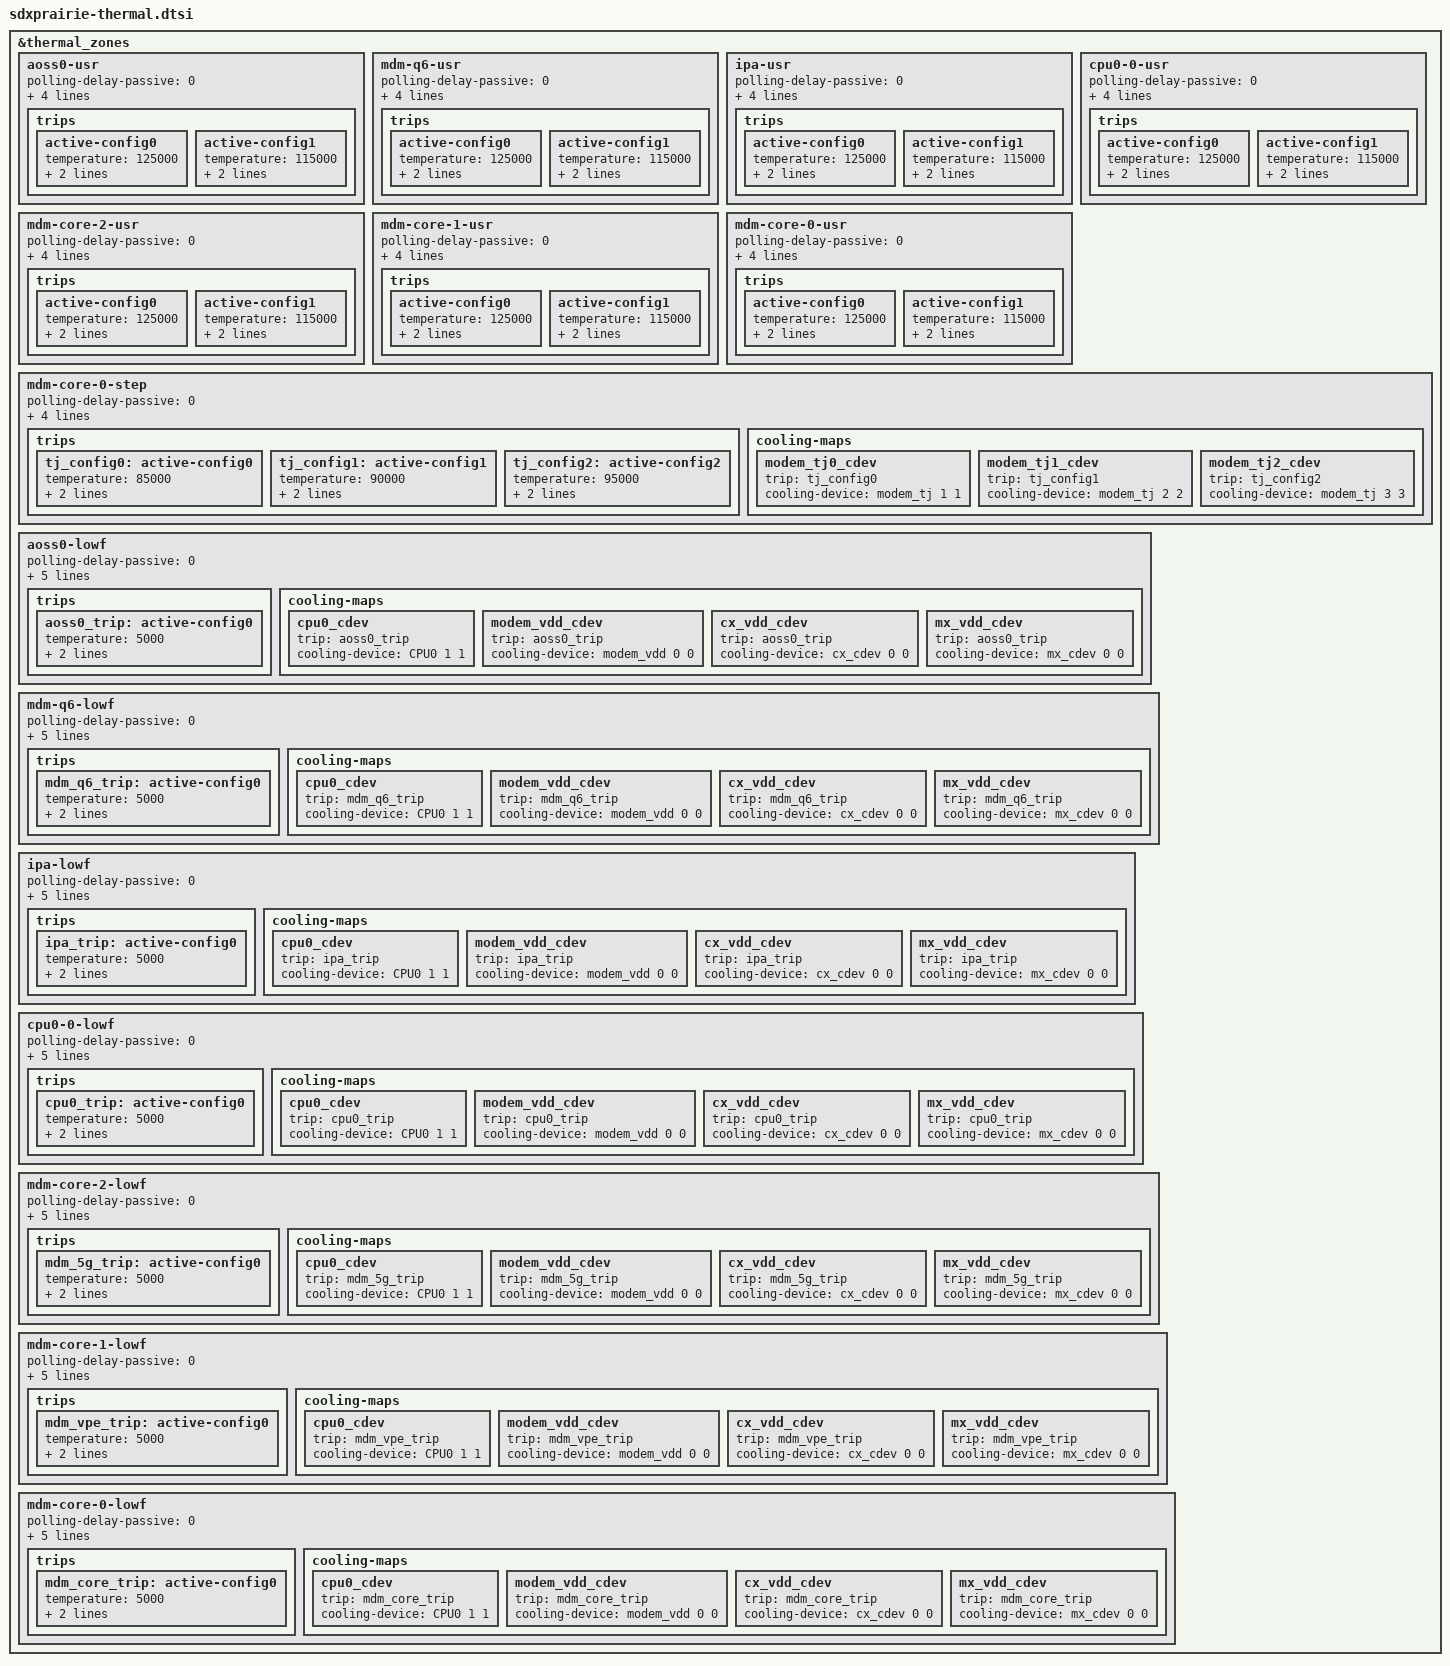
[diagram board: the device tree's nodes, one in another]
/* Copyright (c) 2019-2020, The Linux Foundation. All rights reserved.
 *
 * This program is free software; you can redistribute it and/or modify
 * it under the terms of the GNU General Public License version 2 and
 * only version 2 as published by the Free Software Foundation.
 *
 * This program is distributed in the hope that it will be useful,
 * but WITHOUT ANY WARRANTY; without even the implied warranty of
 * MERCHANTABILITY or FITNESS FOR A PARTICULAR PURPOSE.  See the
 * GNU General Public License for more details.
 */

#include <dt-bindings/thermal/thermal.h>
#include "sdxprairie-thermal-common.dtsi"

&thermal_zones {
	aoss0-usr {
		polling-delay-passive = <0>;
		polling-delay = <0>;
		thermal-governor = "user_space";
		thermal-sensors = <&tsens0 0>;
		wake-capable-sensor;
		trips {
			active-config0 {
				temperature = <125000>;
				hysteresis = <1000>;
				type = "passive";
			};
			active-config1 {
				temperature = <115000>;
				hysteresis = <5000>;
				type = "passive";
			};
		};
	};

	mdm-q6-usr {
		polling-delay-passive = <0>;
		polling-delay = <0>;
		thermal-governor = "user_space";
		thermal-sensors = <&tsens0 1>;
		wake-capable-sensor;
		trips {
			active-config0 {
				temperature = <125000>;
				hysteresis = <1000>;
				type = "passive";
			};
			active-config1 {
				temperature = <115000>;
				hysteresis = <5000>;
				type = "passive";
			};
		};
	};

	ipa-usr {
		polling-delay-passive = <0>;
		polling-delay = <0>;
		thermal-governor = "user_space";
		thermal-sensors = <&tsens0 2>;
		wake-capable-sensor;
		trips {
			active-config0 {
				temperature = <125000>;
				hysteresis = <1000>;
				type = "passive";
			};
			active-config1 {
				temperature = <115000>;
				hysteresis = <5000>;
				type = "passive";
			};
		};
	};

	cpu0-0-usr {
		polling-delay-passive = <0>;
		polling-delay = <0>;
		thermal-governor = "user_space";
		thermal-sensors = <&tsens0 3>;
		wake-capable-sensor;
		trips {
			active-config0 {
				temperature = <125000>;
				hysteresis = <1000>;
				type = "passive";
			};
			active-config1 {
				temperature = <115000>;
				hysteresis = <5000>;
				type = "passive";
			};
		};
	};

	mdm-core-2-usr {
		polling-delay-passive = <0>;
		polling-delay = <0>;
		thermal-sensors = <&tsens0 4>;
		thermal-governor = "user_space";
		wake-capable-sensor;
		trips {
			active-config0 {
				temperature = <125000>;
				hysteresis = <1000>;
				type = "passive";
			};
			active-config1 {
				temperature = <115000>;
				hysteresis = <5000>;
				type = "passive";
			};
		};
	};

	mdm-core-1-usr {
		polling-delay-passive = <0>;
		polling-delay = <0>;
		thermal-sensors = <&tsens0 5>;
		thermal-governor = "user_space";
		wake-capable-sensor;
		trips {
			active-config0 {
				temperature = <125000>;
				hysteresis = <1000>;
				type = "passive";
			};
			active-config1 {
				temperature = <115000>;
				hysteresis = <5000>;
				type = "passive";
			};
		};
	};

	mdm-core-0-usr {
		polling-delay-passive = <0>;
		polling-delay = <0>;
		thermal-sensors = <&tsens0 6>;
		thermal-governor = "user_space";
		wake-capable-sensor;
		trips {
			active-config0 {
				temperature = <125000>;
				hysteresis = <1000>;
				type = "passive";
			};
			active-config1 {
				temperature = <115000>;
				hysteresis = <5000>;
				type = "passive";
			};
		};
	};

	mdm-core-0-step {
		polling-delay-passive = <0>;
		polling-delay = <0>;
		thermal-sensors = <&tsens0 6>;
		thermal-governor = "step_wise";
		wake-capable-sensor;
		trips {
			tj_config0: active-config0 {
				temperature = <85000>;
				hysteresis = <3000>;
				type = "passive";
			};

			tj_config1: active-config1 {
				temperature = <90000>;
				hysteresis = <7000>;
				type = "passive";
			};

			tj_config2: active-config2 {
				temperature = <95000>;
				hysteresis = <7000>;
				type = "passive";
			};
		};

		cooling-maps {
			modem_tj0_cdev {
				trip = <&tj_config0>;
				cooling-device = <&modem_tj 1 1>;
			};

			modem_tj1_cdev {
				trip = <&tj_config1>;
				cooling-device = <&modem_tj 2 2>;
			};

			modem_tj2_cdev {
				trip = <&tj_config2>;
				cooling-device = <&modem_tj 3 3>;
			};
		};
	};

	aoss0-lowf {
		polling-delay-passive = <0>;
		polling-delay = <0>;
		thermal-governor = "low_limits_floor";
		thermal-sensors = <&tsens0 0>;
		wake-capable-sensor;
		tracks-low;
		trips {
			aoss0_trip: active-config0 {
				temperature = <5000>;
				hysteresis = <5000>;
				type = "passive";
			};
		};
		cooling-maps {
			cpu0_cdev {
				trip = <&aoss0_trip>;
				cooling-device = <&CPU0 1 1>;
			};
			modem_vdd_cdev {
				trip = <&aoss0_trip>;
				cooling-device = <&modem_vdd 0 0>;
			};
			cx_vdd_cdev {
				trip = <&aoss0_trip>;
				cooling-device = <&cx_cdev 0 0>;
			};
			mx_vdd_cdev {
				trip = <&aoss0_trip>;
				cooling-device = <&mx_cdev 0 0>;
			};
		};
	};

	mdm-q6-lowf {
		polling-delay-passive = <0>;
		polling-delay = <0>;
		thermal-governor = "low_limits_floor";
		thermal-sensors = <&tsens0 1>;
		wake-capable-sensor;
		tracks-low;
		trips {
			mdm_q6_trip: active-config0 {
				temperature = <5000>;
				hysteresis = <5000>;
				type = "passive";
			};
		};
		cooling-maps {
			cpu0_cdev {
				trip = <&mdm_q6_trip>;
				cooling-device = <&CPU0 1 1>;
			};
			modem_vdd_cdev {
				trip = <&mdm_q6_trip>;
				cooling-device = <&modem_vdd 0 0>;
			};
			cx_vdd_cdev {
				trip = <&mdm_q6_trip>;
				cooling-device = <&cx_cdev 0 0>;
			};
			mx_vdd_cdev {
				trip = <&mdm_q6_trip>;
				cooling-device = <&mx_cdev 0 0>;
			};
		};
	};

	ipa-lowf {
		polling-delay-passive = <0>;
		polling-delay = <0>;
		thermal-governor = "low_limits_floor";
		thermal-sensors = <&tsens0 2>;
		wake-capable-sensor;
		tracks-low;
		trips {
			ipa_trip: active-config0 {
				temperature = <5000>;
				hysteresis = <5000>;
				type = "passive";
			};
		};
		cooling-maps {
			cpu0_cdev {
				trip = <&ipa_trip>;
				cooling-device = <&CPU0 1 1>;
			};
			modem_vdd_cdev {
				trip = <&ipa_trip>;
				cooling-device = <&modem_vdd 0 0>;
			};
			cx_vdd_cdev {
				trip = <&ipa_trip>;
				cooling-device = <&cx_cdev 0 0>;
			};
			mx_vdd_cdev {
				trip = <&ipa_trip>;
				cooling-device = <&mx_cdev 0 0>;
			};
		};
	};

	cpu0-0-lowf {
		polling-delay-passive = <0>;
		polling-delay = <0>;
		thermal-governor = "low_limits_floor";
		thermal-sensors = <&tsens0 3>;
		wake-capable-sensor;
		tracks-low;
		trips {
			cpu0_trip: active-config0 {
				temperature = <5000>;
				hysteresis = <5000>;
				type = "passive";
			};
		};
		cooling-maps {
			cpu0_cdev {
				trip = <&cpu0_trip>;
				cooling-device = <&CPU0 1 1>;
			};
			modem_vdd_cdev {
				trip = <&cpu0_trip>;
				cooling-device = <&modem_vdd 0 0>;
			};
			cx_vdd_cdev {
				trip = <&cpu0_trip>;
				cooling-device = <&cx_cdev 0 0>;
			};
			mx_vdd_cdev {
				trip = <&cpu0_trip>;
				cooling-device = <&mx_cdev 0 0>;
			};
		};
	};

	mdm-core-2-lowf {
		polling-delay-passive = <0>;
		polling-delay = <0>;
		thermal-sensors = <&tsens0 4>;
		thermal-governor = "low_limits_floor";
		wake-capable-sensor;
		tracks-low;
		trips {
			mdm_5g_trip: active-config0 {
				temperature = <5000>;
				hysteresis = <5000>;
				type = "passive";
			};
		};
		cooling-maps {
			cpu0_cdev {
				trip = <&mdm_5g_trip>;
				cooling-device = <&CPU0 1 1>;
			};
			modem_vdd_cdev {
				trip = <&mdm_5g_trip>;
				cooling-device = <&modem_vdd 0 0>;
			};
			cx_vdd_cdev {
				trip = <&mdm_5g_trip>;
				cooling-device = <&cx_cdev 0 0>;
			};
			mx_vdd_cdev {
				trip = <&mdm_5g_trip>;
				cooling-device = <&mx_cdev 0 0>;
			};
		};
	};

	mdm-core-1-lowf {
		polling-delay-passive = <0>;
		polling-delay = <0>;
		thermal-sensors = <&tsens0 5>;
		thermal-governor = "low_limits_floor";
		wake-capable-sensor;
		tracks-low;
		trips {
			mdm_vpe_trip: active-config0 {
				temperature = <5000>;
				hysteresis = <5000>;
				type = "passive";
			};
		};
		cooling-maps {
			cpu0_cdev {
				trip = <&mdm_vpe_trip>;
				cooling-device = <&CPU0 1 1>;
			};
			modem_vdd_cdev {
				trip = <&mdm_vpe_trip>;
				cooling-device = <&modem_vdd 0 0>;
			};
			cx_vdd_cdev {
				trip = <&mdm_vpe_trip>;
				cooling-device = <&cx_cdev 0 0>;
			};
			mx_vdd_cdev {
				trip = <&mdm_vpe_trip>;
				cooling-device = <&mx_cdev 0 0>;
			};
		};
	};

	mdm-core-0-lowf {
		polling-delay-passive = <0>;
		polling-delay = <0>;
		thermal-sensors = <&tsens0 6>;
		thermal-governor = "low_limits_floor";
		wake-capable-sensor;
		tracks-low;
		trips {
			mdm_core_trip: active-config0 {
				temperature = <5000>;
				hysteresis = <5000>;
				type = "passive";
			};
		};
		cooling-maps {
			cpu0_cdev {
				trip = <&mdm_core_trip>;
				cooling-device = <&CPU0 1 1>;
			};
			modem_vdd_cdev {
				trip = <&mdm_core_trip>;
				cooling-device = <&modem_vdd 0 0>;
			};
			cx_vdd_cdev {
				trip = <&mdm_core_trip>;
				cooling-device = <&cx_cdev 0 0>;
			};
			mx_vdd_cdev {
				trip = <&mdm_core_trip>;
				cooling-device = <&mx_cdev 0 0>;
			};
		};
	};
};
